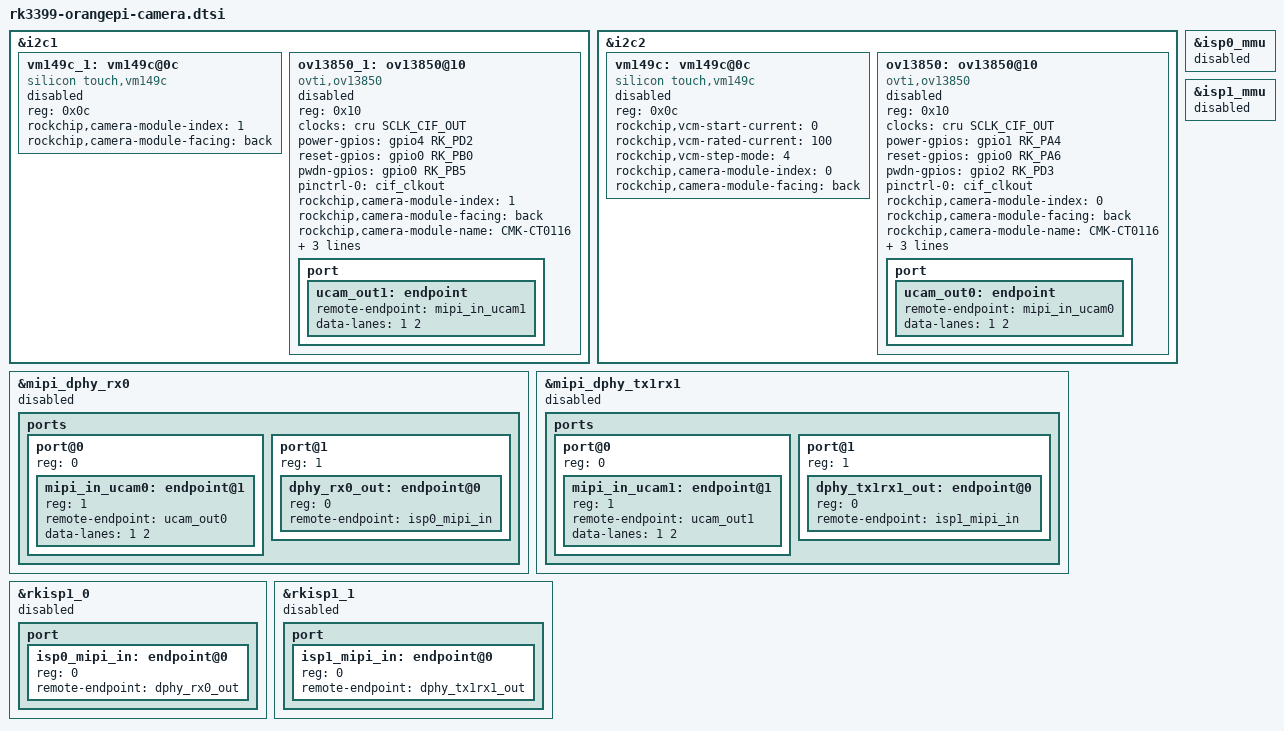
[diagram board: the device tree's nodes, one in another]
&i2c1 {
	status = "okay";

	vm149c_1: vm149c@0c {
		compatible = "silicon touch,vm149c";
		status = "disabled";
		reg = <0x0c>;
		rockchip,camera-module-index = <1>;
		rockchip,camera-module-facing = "back";
	};

	ov13850_1: ov13850@10 {
		compatible = "ovti,ov13850";
		status = "disabled";
		reg = <0x10>;
		clocks = <&cru SCLK_CIF_OUT>;
		clock-names = "xvclk";

		power-gpios = <&gpio4 RK_PD2 GPIO_ACTIVE_HIGH>;
		reset-gpios = <&gpio0 RK_PB0 GPIO_ACTIVE_HIGH>;
		pwdn-gpios = <&gpio0 RK_PB5 GPIO_ACTIVE_HIGH>;
		pinctrl-names = "rockchip,camera_default";
		pinctrl-0 = <&cif_clkout>;
		rockchip,camera-module-index = <1>;
		rockchip,camera-module-facing = "back";
		rockchip,camera-module-name = "CMK-CT0116";
		rockchip,camera-module-lens-name = "Largan-50013A1";
		lens-focus = <&vm149c_1>;

		port {
			ucam_out1: endpoint {
				remote-endpoint = <&mipi_in_ucam1>;
				data-lanes = <1 2>;
			};
		};
	};
};

&i2c2 {
	status = "okay";

	vm149c: vm149c@0c {
		compatible = "silicon touch,vm149c";
		status = "disabled";
		reg = <0x0c>;
		rockchip,vcm-start-current = <0>;
		rockchip,vcm-rated-current = <100>;
		rockchip,vcm-step-mode = <4>;
		rockchip,camera-module-index = <0>;
		rockchip,camera-module-facing = "back";
	};

	ov13850: ov13850@10 {
		compatible = "ovti,ov13850";
		status = "disabled";
		reg = <0x10>;
		clocks = <&cru SCLK_CIF_OUT>;
		clock-names = "xvclk";

		power-gpios = <&gpio1 RK_PA4 GPIO_ACTIVE_HIGH>;
		reset-gpios = <&gpio0 RK_PA6 GPIO_ACTIVE_HIGH>;
		pwdn-gpios = <&gpio2 RK_PD3 GPIO_ACTIVE_HIGH>;
		pinctrl-names = "rockchip,camera_default";
		pinctrl-0 = <&cif_clkout>;
		rockchip,camera-module-index = <0>;
		rockchip,camera-module-facing = "back";
		rockchip,camera-module-name = "CMK-CT0116";
		rockchip,camera-module-lens-name = "Largan-50013A1";
		lens-focus = <&vm149c>;

		port {
			ucam_out0: endpoint {
				remote-endpoint = <&mipi_in_ucam0>;
				data-lanes = <1 2>;
			};
		};
	};
};

&mipi_dphy_rx0 {
	status = "disabled";

	ports {
		#address-cells = <1>;
		#size-cells = <0>;

		port@0 {
			reg = <0>;
			#address-cells = <1>;
			#size-cells = <0>;

			mipi_in_ucam0: endpoint@1 {
				reg = <1>;
				remote-endpoint = <&ucam_out0>;
				data-lanes = <1 2>;
			};
		};

		port@1 {
			reg = <1>;
			#address-cells = <1>;
			#size-cells = <0>;

			dphy_rx0_out: endpoint@0 {
				reg = <0>;
				remote-endpoint = <&isp0_mipi_in>;
			};
		};
	};
};

&mipi_dphy_tx1rx1 {
	status = "disabled";

	ports {
		#address-cells = <1>;
		#size-cells = <0>;

		port@0 {
			reg = <0>;
			#address-cells = <1>;
			#size-cells = <0>;

			mipi_in_ucam1: endpoint@1 {
				reg = <1>;
				remote-endpoint = <&ucam_out1>;
				data-lanes = <1 2>;
			};
		};

		port@1 {
			reg = <1>;
			#address-cells = <1>;
			#size-cells = <0>;

			dphy_tx1rx1_out: endpoint@0 {
				reg = <0>;
				remote-endpoint = <&isp1_mipi_in>;
			};
		};
	};
};

&rkisp1_0 {
	status = "disabled";

	port {
		#address-cells = <1>;
		#size-cells = <0>;

		isp0_mipi_in: endpoint@0 {
			reg = <0>;
			remote-endpoint = <&dphy_rx0_out>;
		};
	};
};

&rkisp1_1 {
	status = "disabled";

        port {
		#address-cells = <1>;
		#size-cells = <0>;

		isp1_mipi_in: endpoint@0 {
			reg = <0>;
			remote-endpoint = <&dphy_tx1rx1_out>;
		};
	};
};

&isp0_mmu {
	status = "disabled";
};

&isp1_mmu {
	status = "disabled";
};
